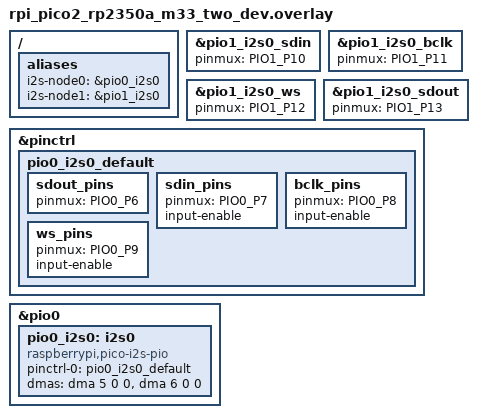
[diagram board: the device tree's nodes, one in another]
/*
 * Two-device GPIO-loopback variant: exercises the PIO I2S driver in target mode.
 *
 *   i2s-node1 = pio1 -> TX, clock CONTROLLER (drives BCLK/WS)
 *   i2s-node0 = pio0 -> RX, clock TARGET     (recovers BCLK/WS from the pins)
 *
 * configure_stream() in src/common.c assigns those roles; main.c only ever
 * configures node0 for RX and node1 for TX. Both nodes still name a "tx" and an
 * "rx" DMA channel, though, so the driver enables both directions on both
 * instances -- the unused direction on each is simply never configured.
 *
 * Required jumpers:
 *
 *   GP13 (node1 sdout) <---> GP7 (node0 sdin)
 *   GP11 (node1 bclk)  <---> GP8 (node0 bclk)
 *   GP12 (node1 ws)    <---> GP9 (node0 ws)
 *
 * Pin-assignment constraint (driver, not arbitrary): the single target program
 * shared by both directions does `in pins, 1` at in_base+0, `wait n pin, 1` at
 * in_base+1 and `wait n pin, 2` at in_base+2, so sdin_pins / bclk_pins / ws_pins
 * have to be three consecutive pins in that order -- hence 7/8/9 on pio0 and
 * 10/11/12 on pio1. The driver asserts bclk_pins + 1 == ws_pins for every
 * instance and sdin_pins == bclk_pins - 1 for every instance whose "rx" DMA
 * channel is named. Those asserts are why pio1's sdin_pins is repointed below
 * even though this test never receives on pio1: the base overlay parks
 * sdin_pins on sdout_pins' pin for its single-device internal loopback, which
 * is nowhere near the bclk_pins pin used here. The TX side has no such
 * adjacency requirement.
 *
 * This overlay is layered on top of boards/rpi_pico2_rp2350a_m33.overlay, which
 * twister applies automatically for this board target. It repoints the existing
 * pio1 pinctrl groups by label rather than redefining them; all four have to
 * move, since the base overlay's sdout_pins/sdin_pins share a pin and pio1 now
 * needs four distinct ones.
 */

#include <dt-bindings/pinctrl/rpi-pico-rp2350a-pinctrl.h>
#include <zephyr/dt-bindings/dma/rpi-pico-dma-rp2350.h>

/ {
	aliases {
		/* Overrides the base overlay's i2s-node0 = &pio1_i2s0. */
		i2s-node0 = &pio0_i2s0;
		i2s-node1 = &pio1_i2s0;
	};
};


&pio1_i2s0_sdin {
	pinmux = <PIO1_P10>;
};

&pio1_i2s0_bclk {
	pinmux = <PIO1_P11>;
};

&pio1_i2s0_ws {
	pinmux = <PIO1_P12>;
};

&pio1_i2s0_sdout {
	pinmux = <PIO1_P13>;
};


&pinctrl {
	pio0_i2s0_default: pio0_i2s0_default {
		sdout_pins {
			pinmux = <PIO0_P6>;
		};

		sdin_pins {
			pinmux = <PIO0_P7>;
			input-enable;
		};
		bclk_pins {
			pinmux = <PIO0_P8>;
			input-enable;
		};
		ws_pins {
			pinmux = <PIO0_P9>;
			input-enable;
		};
	};
};

&pio0 {
	status = "okay";

	pio0_i2s0: i2s0 {
		compatible = "raspberrypi,pico-i2s-pio";
		status = "okay";

		pinctrl-0 = <&pio0_i2s0_default>;
		pinctrl-names = "default";

		#address-cells = <1>;
		#size-cells = <0>;

		/* Channels 7/8 are taken by pio1_i2s0 in the base overlay. */
		dmas = <&dma 5 0 0>,
		       <&dma 6 0 0>;
		dma-names = "tx", "rx";
	};
};
